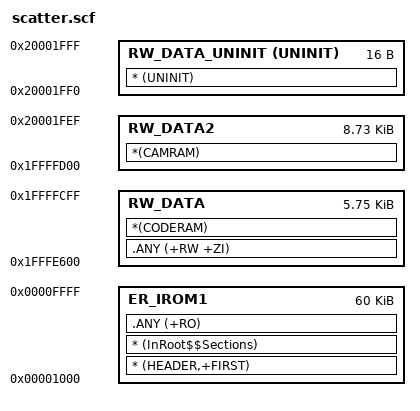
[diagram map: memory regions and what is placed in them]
#! armcc -E
#define m_text_start                   0x00001000
#define m_text_size                    (0x10000 - m_text_start)

; 8KB - 768 bytes for camera - 1.5KB for stack
#define m_data_start                   0x1FFFE600
#define m_data_size                    0x00001700

; 8KB + 768 bytes
#define m_data_2_start                 0x1FFFFD00
#define m_data_2_size                  0x000022F0

#define m_data_uninit_start            0x20001FF0
#define m_data_uninit_size             0x00000010

LR_m_text m_text_start m_text_size {   ; load region size_region
  ER_IROM1 m_text_start m_text_size { ; load address = execution address
    * (HEADER,+FIRST)
    * (InRoot$$Sections)
    .ANY (+RO)
  }
  
  RW_DATA m_data_start m_data_size { ; RW data
    .ANY (+RW +ZI)
    *(CODERAM)
  }
  
  RW_DATA2 m_data_2_start m_data_2_size { ; RW data
    *(CAMRAM)
  }
  
  RW_DATA_UNINIT m_data_uninit_start UNINIT m_data_uninit_size {
    * (UNINIT)
  }
}
